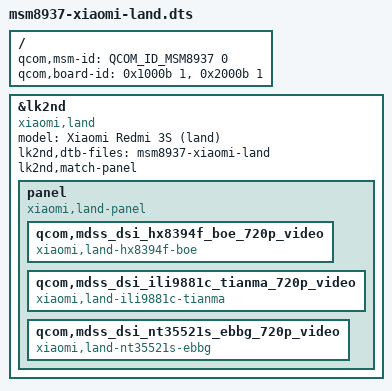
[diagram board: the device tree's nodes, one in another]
// SPDX-License-Identifier: BSD-3-Clause

/dts-v1/;

#include <skeleton64.dtsi>
#include <lk2nd.dtsi>

/ {
	qcom,msm-id = <QCOM_ID_MSM8937 0>;
	qcom,board-id = <0x1000b 1>, <0x2000b 1>;
};

&lk2nd {
	model = "Xiaomi Redmi 3S (land)";
	compatible = "xiaomi,land";

	lk2nd,dtb-files = "msm8937-xiaomi-land";

	lk2nd,match-panel;
	panel {
		compatible = "xiaomi,land-panel", "lk2nd,panel";

		qcom,mdss_dsi_hx8394f_boe_720p_video {
			compatible = "xiaomi,land-hx8394f-boe";
		};
		qcom,mdss_dsi_ili9881c_tianma_720p_video {
			compatible = "xiaomi,land-ili9881c-tianma";
		};
		qcom,mdss_dsi_nt35521s_ebbg_720p_video {
			compatible = "xiaomi,land-nt35521s-ebbg";
		};
	};
};
